# VL6180 register map
Vendor: STMicroelectronics; File version: 1.0
Proximity and ambient light sensing (ALS) module
Registers are 8-bit, read-write, reset 0x0 unless marked. A register's access mark holds for its fields unless they carry their own. Offsets are from the block's base; lines under a group give offsets from that group; [hi:lo] are bit positions; {n}, {i} and the like mark numbered series; 'fields as' and 'values as' point back to an identical list; <NAME> marks a mode.

## Memory map
0x00000000 ALL — Main Peripheral

## ALL — Main Peripheral
Base 0x00000000
0x00 identification_model_id reset 0xB4 — Device model identification number. 0xB4 = VL6180X
0x01 identification_model_rev_major reset 0x1 — Revision identifier of the Device for major change
  [2:0] value
0x02 identification_model_rev_minor reset 0x3 — Revision identifier of the Device for minor change. IDENTIFICATION_MODEL_REV_MINOR = 3 for latest ROM revision
  [2:0] value
0x03 identification_module_rev_major reset 0x1 — Revision identifier of the Module Package for major change. Used to store NVM content version. Contact ST for current information
  [2:0] value
0x04 identification_module_rev_minor reset 0x2 — Revision identifier of the Module Package for minor change. Used to store NVM content version. Contact ST for current information
  [2:0] value
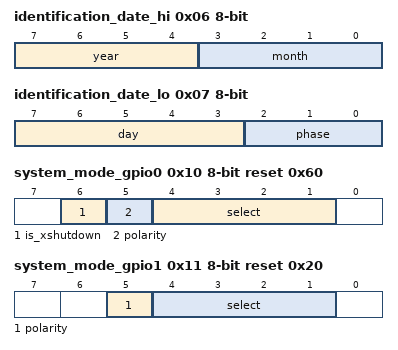
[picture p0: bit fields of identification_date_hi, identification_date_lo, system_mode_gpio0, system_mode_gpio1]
0x06 identification_date_hi — Part of the register set that can be used to uniquely identify a module
  [7:4] year — Last digit of manufacturing year
  [3:0] month — Manufacturing month
0x07 identification_date_lo — Part of the register set that can be used to uniquely identify a module
  [7:3] day — Manufacturing day
  [2:0] phase — Manufacturing phase identification
0x08 identification_time 16-bit — Time since midnight (in seconds) = register_value * 2
  [2:0] value
0x10 system_mode_gpio0 reset 0x60 — Configures polarity and select which function gpio 0 serves
  [6] is_xshutdown — Priority mode - when enabled, other bits of the register are ignored. GPIO0 is main XSHUTDOWN input.
    0=disabled; 1=enabled (GPIO0 is main XSHUTDOWN input)
  [5] polarity — Signal Polarity Selection
    0=low (Active-low); 1=high (Active-high)
  [4:1] select — Functional configuration options
    0=off (Hi-Z); 8=interrupt_output (GPIO Interrupt output)
0x11 system_mode_gpio1 reset 0x20 — Configures polarity and select which function gpio 0 serves
  [5] polarity — Signal Polarity Selection
    0=low (Active-low); 1=high (Active-high)
  [4:1] select — Functional configuration options
    0=off (Hi-Z); 8=interrupt_output (GPIO Interrupt output)
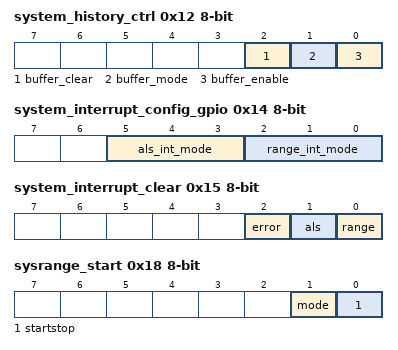
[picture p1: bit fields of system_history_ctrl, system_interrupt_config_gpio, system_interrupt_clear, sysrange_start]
0x12 system_history_ctrl
  [2] buffer_clear — User-command to clear history (FW will auto-clear this bit when clear has completed)
    0=disabled; 1=clear_all
  [1] buffer_mode — Select mode buffer results for:
    0=ranging; 1=als
  [0] buffer_enable — Enable History buffering
    0=disabled; 1=enabled
0x14 system_interrupt_config_gpio
  [5:3] als_int_mode — Interrupt mode source for ALS readings
    0=disabled; 1=level_low (value less then thresh_low); 2=level_high (value more then thresh_high); 3=out_of_window (value less then thresh_low OR value more then thresh_high); 4=new_sample_ready
  [2:0] range_int_mode — Interrupt mode source for Range readings
    values as als_int_mode
0x15 system_interrupt_clear
  [2] error — Clear Error Int
  [1] als — Clear ALS Int
  [0] range — Clear Range Int
0x16 system_fresh_out_of_reset reset 0x1 — Fresh out of reset bit, default of 1, user can set this to 0 after initial boot and can therefore use this to check for a reset condition
  [0] value — Fresh out of reset bit
0x17 system_grouped_parameter_hold — Flag set over I2C to indicate that data is being updated
  [0] value — GROUPED_PARAMETER_HOLD
    0=stable (Data is stable - FW is safe to copy); 1=updated (Data being updated - FW not safe to copy)
0x18 sysrange_start
  [1] mode — Device Mode select
    0=single_shot (Ranging Mode Single-Shot); 1=continuous (Ranging Mode Continuous)
  [0] startstop — StartStop trigger based on current mode and system configuration of device_ready. FW clears register automatically. This bit is auto-cleared in both modes of operation.
0x19 sysrange_thresh_high reset 0xFF — High Threshold value for ranging comparison. Range 0-255mm
0x1A sysrange_thresh_low — Low Threshold value for ranging comparison. Range 0-255mm
0x1B sysrange_intermeasurement_period reset 0xFF — Time delay between measurements in Ranging continuous mode. Range 0-254 (0 = 10ms). Step size = 10ms
0x1C sysrange_max_convergence_time reset 0x31 — Maximum time to run measurement in Ranging modes. 1 code = 1 ms. Measurement aborted when limit reached to aid power reduction
  [5:0] value range 1..63
0x1E sysrange_crosstalk_compensation_rate 16-bit — User-controlled crosstalk compensation in Mcps (9.7 format)
0x21 sysrange_crosstalk_valid_height reset 0x14 — Minimum range value in mm to qualify for cross-talk compensation
0x22 sysrange_early_convergence_estimate 16-bit — FW carries out an estimate of convergence rate 0.5ms into each new range measurement. If convergence rate is below user input value, the operation aborts to save power
0x24 sysrange_part_to_part_range_offset — 2s complement format
0x25 sysrange_range_ignore_valid_height reset 0x10 — Range below which ignore threshold is applied. Aim is to ignore the cover glass i.e. low signal rate at near distance. Should not be applied to low reflectance target at far distance. Range in mm
0x26 sysrange_range_ignore_threshold 16-bit — User configurable min threshold signal return rate. Used to filter out ranging due to cover glass when there is no target above the device. Mcps 9.7 format
0x2C sysrange_max_ambient_level_mult reset 0xA0 — User input value to multiply return_signal_count for AMB:signal ratio check. If (amb counts * 6) > return_signal_count * mult then abandon measurement due to high ambient (4.4 format)
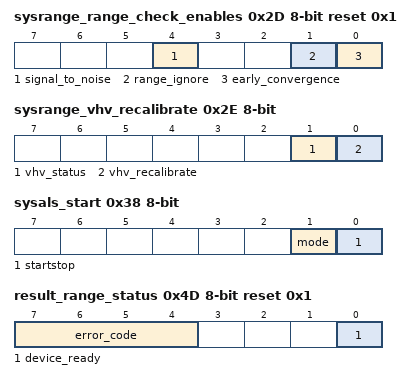
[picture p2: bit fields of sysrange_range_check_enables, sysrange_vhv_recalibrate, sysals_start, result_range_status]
0x2D sysrange_range_check_enables reset 0x11
  [4] signal_to_noise, [1] range_ignore, [0] early_convergence
0x2E sysrange_vhv_recalibrate
  [1] vhv_status — FW controlled status bit showing when FW has completed auto-vhv process
    0=finished (FW has finished autoVHV operation); 1=operation (During autoVHV operation)
  [0] vhv_recalibrate — User-Controlled enable bit to force FW to carry out recalibration of the VHV setting for sensor array. FW clears bit after operation carried out
    1=start (Manual trigger for VHV recalibration. Can only be called when ALS and ranging are in STOP mode)
0x31 sysrange_vhv_repeate_rate — User entered repeat rate of auto VHV task (0 = off, 255 = after every 255 measurements)
0x38 sysals_start
  [1] mode — Device Mode select
    0=single_shot (ALS Mode Single-Shot); 1=continious (ALS Mode Continuous)
  [0] startstop — Start/Stop trigger based on current mode and system configuration of device_ready. FW clears register automatically
    1=enable (In single-shot mode starts a single measurement. In continuous mode will either start continuous operation (if stopped) or halt continuous operation (if started))
0x3A sysals_thresh_high 16-bit reset 0xFFFF — High Threshold value for ALS comparison. Range 0-65535 codes
0x3C sysals_thresh_low 16-bit — Low Threshold value for ALS comparison. Range 0-65535 codes
0x3E sysals_intermeasurement_period reset 0xFF — Time delay between measurements in ALS continuous mode. Range 0-254 (0 = 10ms). Step size = 10ms
0x3F sysals_analogue_gain reset 0x6
  [2:0] light — ALS analogue gain (light channel)
    0=gain20 (ALS Gain = 20); 1=gain10 (ALS Gain = 10); 2=gain5 (ALS Gain = 5.0); 3=gain2_5 (ALS Gain = 2.5); 4=gain1_67 (ALS Gain = 1.67); 5=gain1_25 (ALS Gain = 1.25); 6=gain1 (ALS Gain = 1.0); 7=gain40 (ALS Gain = 40)
0x40 sysals_integration_period — Integration period for ALS mode. 1 code = 1 ms (0 = 1 ms). Recommended setting is 100 ms (0x63)
  [7:0] value
0x4D result_range_status ro reset 0x1
  [7:4] error_code — Specific error codes
    0=no (No error); 1=vcsel_continuity_test; 2=vcsel_watchdog_test; 3=vcsel_watchdog; 4=pll1_lock; 5=pll2_lock; 6=early_convergence_estimate; 7=max_convergence; 8=no_target_ignore; 11=max_snr (Max Signal To Noise Ratio); 12=raw_ranging_algo_underflow; 13=raw_ranging_algo_overflow; 14=ranging_algo_underflow; 15=ranging_algo_overflow
  [0] device_ready — Device Ready. When set to 1, indicates the device mode and configuration can be changed and a new start command will be accepted. When 0, indicates the device is busy
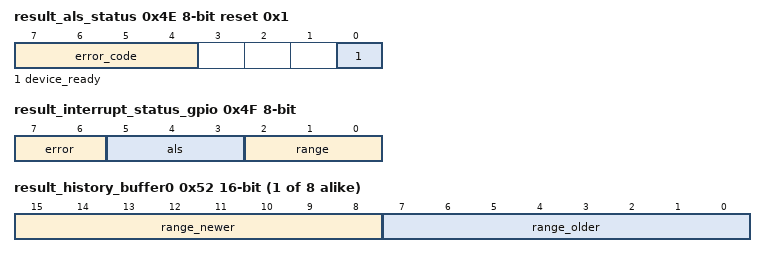
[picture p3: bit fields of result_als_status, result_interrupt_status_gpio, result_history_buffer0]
0x4E result_als_status ro reset 0x1
  [7:4] error_code — Specific error and debug codes
    0=no (No error); 1=Overflow error; 2=Underflow error
  [0] device_ready — Device Ready. When set to 1, indicates the device mode and configuration can be changed and a new start command will be accepted. When 0, indicates the device is busy
0x4F result_interrupt_status_gpio ro
  [7:6] error — Interrupt bits for Error
    0=no (No error reported); 1=Laser Safety Error; 2=pll (PLL error (either PLL1 or PLL2))
  [5:3] als — Interrupt bits for ALS
    0=no (No threshold events reported); 1=Level Low threshold event; 2=Level High threshold event; 3=Out Of Window threshold event; 4=New Sample Ready threshold event
  [2:0] range — Interrupt bits for Range
    values as als
0x50 result_als_val 16-bit ro — 16 Bit ALS count output value. Lux value depends on Gain and integration settings and calibrated lux/count setting
{0x52+2i} result_history_buffer{i} (i=0..7) 16-bit ro — Range/ALS result value
  [15:8] range_newer, [7:0] range_older
0x62 result_range_val ro — Final range result value presented to the user for use. Unit is in mm
0x64 result_range_raw ro — Raw Range result value with offset applied (no cross-talk compensation applied). Unit is in mm
0x66 result_range_return_rate 16-bit ro — Sensor count rate of signal returns correlated to IR emitter. Computed from RETURN_SIGNAL_COUNT / RETURN_CONV_TIME. Mcps 9.7 format
0x68 result_range_reference_rate 16-bit ro — Sensor count rate of reference signal returns. Computed from REFERENCE_SIGNAL_COUNT / RETURN_CONV_TIME. Mcps 9.7 format
0x6C result_range_return_signal_count 32-bit ro — Sensor count output value attributed to signal correlated to IR emitter on the Return array
0x70 result_range_reference_signal_count 32-bit ro — Sensor count output value attributed to signal correlated to IR emitter on the Reference array
0x74 result_range_return_amb_count 32-bit ro — Sensor count output value attributed to uncorrelated ambient signal on the Return array. Must be multiplied by 6 if used to calculate the ambient to signal threshold
0x78 result_range_reference_amb_count 32-bit ro — Sensor count output value attributed to uncorrelated ambient signal on the Reference array
0x7C result_range_return_conv_time 32-bit ro — Sensor count output value attributed to signal on the Return array
0x80 result_range_reference_conv_time 32-bit ro — Sensor count output value attributed to signal on the Reference array
0x10A readout_averaging_sample_period reset 0x30 — The internal readout averaging sample period can be adjusted from 0 to 255. Increasing the sampling period decreases noise but also reduces the effective max convergence time and increases power consumption
0x119 firmware_bootup reset 0x1 — FW must set bit once initial boot has been completed
  [0] value
0x120 firmware_result_scaler reset 0x1 — Analogue gain 1 to 16x
  [3:0] als
0x212 i2c_slave_device_address reset 0x29 — User programmable I 2 C address (7-bit). Device address can be re-designated after power-up
  [7:0] super_address
0x2A3 interleaved_mode_enable — Write 0x1 to this register to select ALS+Range interleaved mode. Use SYSALS_START and SYSALS_INTERMEASUREMENT_PERIOD to control this mode. A range measurement is automatically performed immediately after each ALS measurement
